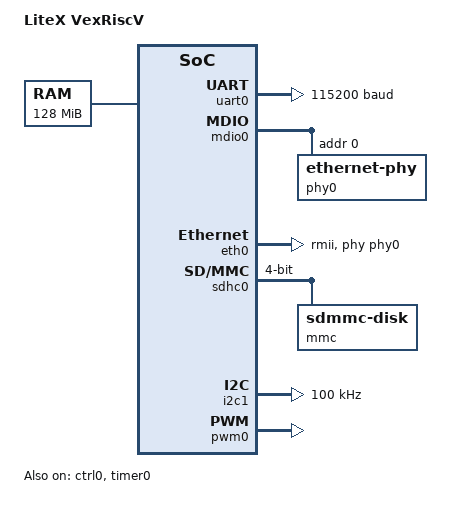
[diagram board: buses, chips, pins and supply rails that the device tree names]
/dts-v1/;

/* node '/' defined in zephyr/dts/riscv/riscv32-litex-vexriscv.dtsi:7 */
/ {
	#address-cells = < 0x1 >;      /* in zephyr/dts/riscv/riscv32-litex-vexriscv.dtsi:8 */
	#size-cells = < 0x1 >;         /* in zephyr/dts/riscv/riscv32-litex-vexriscv.dtsi:9 */
	model = "LiteX VexRiscV";      /* in zephyr/boards/enjoydigital/litex_vexriscv/litex_vexriscv.dts:13 */
	compatible = "litex,vexriscv"; /* in zephyr/boards/enjoydigital/litex_vexriscv/litex_vexriscv.dts:14 */

	/* node '/cpus' defined in zephyr/dts/riscv/riscv32-litex-vexriscv.dtsi:13 */
	cpus {
		#address-cells = < 0x1 >; /* in zephyr/dts/riscv/riscv32-litex-vexriscv.dtsi:14 */
		#size-cells = < 0x0 >;    /* in zephyr/dts/riscv/riscv32-litex-vexriscv.dtsi:15 */

		/* node '/cpus/cpu@0' defined in zephyr/dts/riscv/riscv32-litex-vexriscv.dtsi:17 */
		cpu0: cpu@0 {
			compatible = "litex,vexriscv-standard",
			             "spinalhdl,vexriscv",
			             "riscv";                   /* in zephyr/dts/riscv/riscv32-litex-vexriscv.dtsi:19 */
			device_type = "cpu";                    /* in zephyr/dts/riscv/riscv32-litex-vexriscv.dtsi:20 */
			reg = < 0x0 >;                          /* in zephyr/dts/riscv/riscv32-litex-vexriscv.dtsi:21 */
			riscv,isa-base = "rv32i";               /* in zephyr/dts/riscv/riscv32-litex-vexriscv.dtsi:22 */
			riscv,isa-extensions = "i",
			                       "m",
			                       "zicsr",
			                       "zifencei";      /* in zephyr/dts/riscv/riscv32-litex-vexriscv.dtsi:23 */
			status = "okay";                        /* in zephyr/dts/riscv/riscv32-litex-vexriscv.dtsi:24 */
			clock-frequency = < 0x2dc6c00 >;        /* in ../../build/rtos-system-fit/software/20261006T224900.204514Z/zephyr/generated/csr.overlay.dts:2 */
			i-cache-line-size = < 0x20 >;           /* in ../../build/rtos-system-fit/software/20261006T224900.204514Z/zephyr/generated/csr.overlay.dts:194 */
		};
	};

	/* node '/soc' defined in zephyr/dts/riscv/riscv32-litex-vexriscv.dtsi:28 */
	soc {
		#address-cells = < 0x1 >;      /* in zephyr/dts/riscv/riscv32-litex-vexriscv.dtsi:29 */
		#size-cells = < 0x1 >;         /* in zephyr/dts/riscv/riscv32-litex-vexriscv.dtsi:30 */
		compatible = "litex,vexriscv"; /* in zephyr/dts/riscv/riscv32-litex-vexriscv.dtsi:31 */
		ranges;                        /* in zephyr/dts/riscv/riscv32-litex-vexriscv.dtsi:32 */

		/* node '/soc/interrupt-controller@bc0' defined in zephyr/dts/riscv/riscv32-litex-vexriscv.dtsi:34 */
		intc0: interrupt-controller@bc0 {
			compatible = "litex,vexriscv-intc0"; /* in zephyr/dts/riscv/riscv32-litex-vexriscv.dtsi:35 */
			#address-cells = < 0x0 >;            /* in zephyr/dts/riscv/riscv32-litex-vexriscv.dtsi:36 */
			#interrupt-cells = < 0x2 >;          /* in zephyr/dts/riscv/riscv32-litex-vexriscv.dtsi:37 */
			interrupt-controller;                /* in zephyr/dts/riscv/riscv32-litex-vexriscv.dtsi:38 */
			reg = < 0xbc0 0x4 0xfc0 0x4 >;       /* in zephyr/dts/riscv/riscv32-litex-vexriscv.dtsi:39 */
			reg-names = "irq_mask",
			            "irq_pending";           /* in zephyr/dts/riscv/riscv32-litex-vexriscv.dtsi:40 */
			riscv,max-priority = < 0x7 >;        /* in zephyr/dts/riscv/riscv32-litex-vexriscv.dtsi:41 */
			phandle = < 0x1 >;                   /* in zephyr/boards/enjoydigital/litex_vexriscv/litex_vexriscv.dts:47 */
		};

		/* node '/soc/soc_controller@e0000000' defined in zephyr/boards/enjoydigital/litex_vexriscv/litex_vexriscv.dts:34 */
		ctrl0: soc_controller@e0000000 {
			compatible = "litex,soc-controller"; /* in zephyr/boards/enjoydigital/litex_vexriscv/litex_vexriscv.dts:35 */
			status = "okay";                     /* in zephyr/boards/enjoydigital/litex_vexriscv/litex_vexriscv.dts:42 */
			reg = < 0xf0000000 0x4 >,
			      < 0xf0000004 0x4 >,
			      < 0xf0000008 0x4 >;            /* in ../../build/rtos-system-fit/software/20261006T224900.204514Z/zephyr/generated/csr.overlay.dts:5 */
			reg-names = "reset",
			            "scratch",
			            "bus_errors";            /* in ../../build/rtos-system-fit/software/20261006T224900.204514Z/zephyr/generated/csr.overlay.dts:8 */
		};

		/* node '/soc/serial@e0001800' defined in zephyr/boards/enjoydigital/litex_vexriscv/litex_vexriscv.dts:45 */
		uart0: serial@e0001800 {
			compatible = "litex,uart";     /* in zephyr/boards/enjoydigital/litex_vexriscv/litex_vexriscv.dts:46 */
			interrupt-parent = < &intc0 >; /* in zephyr/boards/enjoydigital/litex_vexriscv/litex_vexriscv.dts:47 */
			status = "okay";               /* in zephyr/boards/enjoydigital/litex_vexriscv/litex_vexriscv.dts:65 */
			current-speed = < 0x1c200 >;   /* in zephyr/boards/enjoydigital/litex_vexriscv/litex_vexriscv.dts:66 */
			reg = < 0xf0004000 0x4 >,
			      < 0xf0004004 0x4 >,
			      < 0xf0004008 0x4 >,
			      < 0xf000400c 0x4 >,
			      < 0xf0004010 0x4 >,
			      < 0xf0004014 0x4 >,
			      < 0xf0004018 0x4 >,
			      < 0xf000401c 0x4 >;      /* in ../../build/rtos-system-fit/software/20261006T224900.204514Z/zephyr/generated/csr.overlay.dts:13 */
			reg-names = "rxtx",
			            "txfull",
			            "rxempty",
			            "ev_status",
			            "ev_pending",
			            "ev_enable",
			            "txempty",
			            "rxfull";          /* in ../../build/rtos-system-fit/software/20261006T224900.204514Z/zephyr/generated/csr.overlay.dts:21 */
			interrupts = < 0x0 0x1 >;      /* in ../../build/rtos-system-fit/software/20261006T224900.204514Z/zephyr/generated/csr.overlay.dts:29 */
		};

		/* node '/soc/timer@e0002800' defined in zephyr/boards/enjoydigital/litex_vexriscv/litex_vexriscv.dts:69 */
		timer0: timer@e0002800 {
			compatible = "litex,timer0";   /* in zephyr/boards/enjoydigital/litex_vexriscv/litex_vexriscv.dts:70 */
			interrupt-parent = < &intc0 >; /* in zephyr/boards/enjoydigital/litex_vexriscv/litex_vexriscv.dts:71 */
			status = "okay";               /* in zephyr/boards/enjoydigital/litex_vexriscv/litex_vexriscv.dts:93 */
			reg = < 0xf0003800 0x4 >,
			      < 0xf0003804 0x4 >,
			      < 0xf0003808 0x4 >,
			      < 0xf000380c 0x4 >,
			      < 0xf0003810 0x4 >,
			      < 0xf0003814 0x4 >,
			      < 0xf0003818 0x4 >,
			      < 0xf000381c 0x4 >,
			      < 0xf0003820 0x4 >,
			      < 0xf0003824 0x8 >;      /* in ../../build/rtos-system-fit/software/20261006T224900.204514Z/zephyr/generated/csr.overlay.dts:32 */
			reg-names = "load",
			            "reload",
			            "en",
			            "update_value",
			            "value",
			            "ev_status",
			            "ev_pending",
			            "ev_enable",
			            "uptime_latch",
			            "uptime_cycles";   /* in ../../build/rtos-system-fit/software/20261006T224900.204514Z/zephyr/generated/csr.overlay.dts:42 */
			interrupts = < 0x1 0x1 >;      /* in ../../build/rtos-system-fit/software/20261006T224900.204514Z/zephyr/generated/csr.overlay.dts:52 */
		};

		/* node '/soc/watchdog@e000d000' defined in zephyr/boards/enjoydigital/litex_vexriscv/litex_vexriscv.dts:96 */
		wdt0: watchdog@e000d000 {
			compatible = "litex,watchdog"; /* in zephyr/boards/enjoydigital/litex_vexriscv/litex_vexriscv.dts:97 */
			interrupt-parent = < &intc0 >; /* in zephyr/boards/enjoydigital/litex_vexriscv/litex_vexriscv.dts:98 */
			reg = < 0xe000d000 0x4 >,
			      < 0xe000d004 0x4 >,
			      < 0xe000d008 0x4 >,
			      < 0xe000d00c 0x4 >,
			      < 0xe000d010 0x4 >,
			      < 0xe000d014 0x4 >;      /* in zephyr/boards/enjoydigital/litex_vexriscv/litex_vexriscv.dts:99 */
			reg-names = "control",
			            "cycles",
			            "remaining",
			            "ev_status",
			            "ev_pending",
			            "ev_enable";       /* in zephyr/boards/enjoydigital/litex_vexriscv/litex_vexriscv.dts:105 */
			interrupts = < 0x8 0xf >;      /* in zephyr/boards/enjoydigital/litex_vexriscv/litex_vexriscv.dts:111 */
			status = "disabled";           /* in ../../build/rtos-system-fit/software/20261006T224900.204514Z/zephyr/generated/csr.overlay.dts:178 */
		};

		/* node '/soc/mdio@e0008000' defined in zephyr/boards/enjoydigital/litex_vexriscv/litex_vexriscv.dts:115 */
		mdio0: mdio@e0008000 {
			compatible = "litex,liteeth-mdio"; /* in zephyr/boards/enjoydigital/litex_vexriscv/litex_vexriscv.dts:116 */
			#address-cells = < 0x1 >;          /* in zephyr/boards/enjoydigital/litex_vexriscv/litex_vexriscv.dts:123 */
			#size-cells = < 0x0 >;             /* in zephyr/boards/enjoydigital/litex_vexriscv/litex_vexriscv.dts:124 */
			status = "okay";                   /* in zephyr/boards/enjoydigital/litex_vexriscv/litex_vexriscv.dts:125 */
			reg = < 0xf0001804 0x4 >,
			      < 0xf0001808 0x4 >;          /* in ../../build/rtos-system-fit/software/20261006T224900.204514Z/zephyr/generated/csr.overlay.dts:90 */
			reg-names = "mdio_w",
			            "mdio_r";              /* in ../../build/rtos-system-fit/software/20261006T224900.204514Z/zephyr/generated/csr.overlay.dts:92 */

			/* node '/soc/mdio@e0008000/ethernet-phy@1' defined in zephyr/boards/enjoydigital/litex_vexriscv/litex_vexriscv.dts:127 */
			phy0: ethernet-phy@1 {
				compatible = "ethernet-phy";            /* in zephyr/boards/enjoydigital/litex_vexriscv/litex_vexriscv.dts:128 */
				status = "okay";                        /* in zephyr/boards/enjoydigital/litex_vexriscv/litex_vexriscv.dts:130 */
				reg = < 0x0 >;                          /* in ../../build/rtos-system-fit/software/20261006T224900.204514Z/zephyr/generated/csr.overlay.dts:197 */
				default-speeds = "10BASE Half-Duplex",
				                 "10BASE Full-Duplex",
				                 "100BASE Half-Duplex",
				                 "100BASE Full-Duplex"; /* in ../../build/rtos-system-fit/software/20261006T224900.204514Z/zephyr/generated/csr.overlay.dts:197 */
				phandle = < 0x2 >;                      /* in zephyr/boards/enjoydigital/litex_vexriscv/litex_vexriscv.dts:169 */
			};
		};

		/* node '/soc/ethernet@e0009800' defined in zephyr/boards/enjoydigital/litex_vexriscv/litex_vexriscv.dts:134 */
		eth0: ethernet@e0009800 {
			compatible = "litex,liteeth";              /* in zephyr/boards/enjoydigital/litex_vexriscv/litex_vexriscv.dts:135 */
			interrupt-parent = < &intc0 >;             /* in zephyr/boards/enjoydigital/litex_vexriscv/litex_vexriscv.dts:136 */
			local-mac-address = [ 10 E2 D5 00 00 02 ]; /* in zephyr/boards/enjoydigital/litex_vexriscv/litex_vexriscv.dts:153 */
			phy-handle = < &phy0 >;                    /* in zephyr/boards/enjoydigital/litex_vexriscv/litex_vexriscv.dts:169 */
			status = "okay";                           /* in zephyr/boards/enjoydigital/litex_vexriscv/litex_vexriscv.dts:170 */
			reg = < 0xf0001000 0x4 >,
			      < 0xf0001004 0x4 >,
			      < 0xf0001008 0x4 >,
			      < 0xf000100c 0x4 >,
			      < 0xf0001010 0x4 >,
			      < 0xf0001014 0x4 >,
			      < 0xf0001018 0x4 >,
			      < 0xf000101c 0x4 >,
			      < 0xf0001020 0x4 >,
			      < 0xf0001024 0x4 >,
			      < 0xf0001028 0x4 >,
			      < 0xf000102c 0x4 >,
			      < 0xf0001030 0x4 >,
			      < 0xf0001034 0x4 >,
			      < 0x80000000 0x800 >,
			      < 0x80000800 0x800 >;                /* in ../../build/rtos-system-fit/software/20261006T224900.204514Z/zephyr/generated/csr.overlay.dts:55 */
			reg-names = "rx_slot",
			            "rx_length",
			            "rx_errors",
			            "rx_ev_status",
			            "rx_ev_pending",
			            "rx_ev_enable",
			            "tx_start",
			            "tx_ready",
			            "tx_level",
			            "tx_slot",
			            "tx_length",
			            "tx_ev_status",
			            "tx_ev_pending",
			            "tx_ev_enable",
			            "rx_buffers",
			            "tx_buffers";                  /* in ../../build/rtos-system-fit/software/20261006T224900.204514Z/zephyr/generated/csr.overlay.dts:71 */
			interrupts = < 0x2 0x1 >;                  /* in ../../build/rtos-system-fit/software/20261006T224900.204514Z/zephyr/generated/csr.overlay.dts:87 */
			phy-connection-type = "rmii";              /* in ../../build/rtos-system-fit/software/20261006T224900.204514Z/zephyr/generated/csr.overlay.dts:196 */
		};

		/* node '/soc/dna@e0003800' defined in zephyr/boards/enjoydigital/litex_vexriscv/litex_vexriscv.dts:173 */
		dna0: dna@e0003800 {
			compatible = "litex,dna0"; /* in zephyr/boards/enjoydigital/litex_vexriscv/litex_vexriscv.dts:174 */
			reg = < 0xe0003800 0x20 >; /* in zephyr/boards/enjoydigital/litex_vexriscv/litex_vexriscv.dts:181 */
			reg-names = "mem";         /* in zephyr/boards/enjoydigital/litex_vexriscv/litex_vexriscv.dts:182 */
			status = "disabled";       /* in ../../build/rtos-system-fit/software/20261006T224900.204514Z/zephyr/generated/csr.overlay.dts:187 */
		};

		/* node '/soc/spi@e0002000' defined in zephyr/boards/enjoydigital/litex_vexriscv/litex_vexriscv.dts:186 */
		spi0: spi@e0002000 {
			compatible = "litex,spi"; /* in zephyr/boards/enjoydigital/litex_vexriscv/litex_vexriscv.dts:187 */
			reg = < 0xe0002000 0x4 >,
			      < 0xe0002004 0x4 >,
			      < 0xe0002008 0x4 >,
			      < 0xe000200c 0x4 >,
			      < 0xe0002010 0x4 >,
			      < 0xe0002014 0x4 >; /* in zephyr/boards/enjoydigital/litex_vexriscv/litex_vexriscv.dts:188 */
			reg-names = "control",
			            "status",
			            "mosi",
			            "miso",
			            "cs",
			            "loopback";   /* in zephyr/boards/enjoydigital/litex_vexriscv/litex_vexriscv.dts:194 */
			#address-cells = < 0x1 >; /* in zephyr/boards/enjoydigital/litex_vexriscv/litex_vexriscv.dts:201 */
			#size-cells = < 0x0 >;    /* in zephyr/boards/enjoydigital/litex_vexriscv/litex_vexriscv.dts:202 */
			status = "disabled";      /* in ../../build/rtos-system-fit/software/20261006T224900.204514Z/zephyr/generated/csr.overlay.dts:96 */
		};

		/* node '/soc/spi@e000c000' defined in zephyr/boards/enjoydigital/litex_vexriscv/litex_vexriscv.dts:205 */
		spi1: spi@e000c000 {
			compatible = "litex,spi-litespi"; /* in zephyr/boards/enjoydigital/litex_vexriscv/litex_vexriscv.dts:206 */
			interrupt-parent = < &intc0 >;    /* in zephyr/boards/enjoydigital/litex_vexriscv/litex_vexriscv.dts:207 */
			reg = < 0xe000c000 0x4 >,
			      < 0xe000c004 0x4 >,
			      < 0xe000c008 0x4 >,
			      < 0xe000c00c 0x4 >,
			      < 0xe000c010 0x4 >,
			      < 0xe000c014 0x4 >,
			      < 0xe000c018 0x4 >,
			      < 0xe000c01c 0x4 >,
			      < 0xe000c020 0x4 >,
			      < 0x60000000 0x1000000 >;   /* in zephyr/boards/enjoydigital/litex_vexriscv/litex_vexriscv.dts:208 */
			reg-names = "phy_clk_divisor",
			            "mmap_dummy_bits",
			            "master_cs",
			            "master_phyconfig",
			            "master_rxtx",
			            "master_status",
			            "master_ev_status",
			            "master_ev_pending",
			            "master_ev_enable",
			            "flash_mmap";         /* in zephyr/boards/enjoydigital/litex_vexriscv/litex_vexriscv.dts:218 */
			interrupts = < 0x9 0x0 >;         /* in zephyr/boards/enjoydigital/litex_vexriscv/litex_vexriscv.dts:228 */
			#address-cells = < 0x1 >;         /* in zephyr/boards/enjoydigital/litex_vexriscv/litex_vexriscv.dts:229 */
			#size-cells = < 0x0 >;            /* in zephyr/boards/enjoydigital/litex_vexriscv/litex_vexriscv.dts:230 */
			status = "disabled";              /* in ../../build/rtos-system-fit/software/20261006T224900.204514Z/zephyr/generated/csr.overlay.dts:99 */

			/* node '/soc/spi@e000c000/flash@0' defined in zephyr/boards/enjoydigital/litex_vexriscv/litex_vexriscv.dts:232 */
			spiflash0: flash@0 {
				compatible = "jedec,spi-nor";     /* in zephyr/boards/enjoydigital/litex_vexriscv/litex_vexriscv.dts:233 */
				reg = < 0x0 >;                    /* in zephyr/boards/enjoydigital/litex_vexriscv/litex_vexriscv.dts:234 */
				spi-max-frequency = < 0x989680 >; /* in zephyr/boards/enjoydigital/litex_vexriscv/litex_vexriscv.dts:235 */
			};
		};

		/* node '/soc/sdhc@e000e800' defined in zephyr/boards/enjoydigital/litex_vexriscv/litex_vexriscv.dts:239 */
		sdhc0: sdhc@e000e800 {
			compatible = "litex,mmc";           /* in zephyr/boards/enjoydigital/litex_vexriscv/litex_vexriscv.dts:240 */
			interrupt-parent = < &intc0 >;      /* in zephyr/boards/enjoydigital/litex_vexriscv/litex_vexriscv.dts:241 */
			status = "okay";                    /* in zephyr/boards/enjoydigital/litex_vexriscv/litex_vexriscv.dts:303 */
			reg = < 0xf0002800 0x4 >,
			      < 0xf0002804 0x4 >,
			      < 0xf0002808 0x4 >,
			      < 0xf000280c 0x4 >,
			      < 0xf0002810 0x4 >,
			      < 0xf0002814 0x4 >,
			      < 0xf0002818 0x4 >,
			      < 0xf000281c 0x4 >,
			      < 0xf0002820 0x4 >,
			      < 0xf0002824 0x4 >,
			      < 0xf0002828 0x10 >,
			      < 0xf0002838 0x4 >,
			      < 0xf000283c 0x4 >,
			      < 0xf0002840 0x4 >,
			      < 0xf0002844 0x4 >,
			      < 0xf0002848 0x8 >,
			      < 0xf0002850 0x4 >,
			      < 0xf0002854 0x4 >,
			      < 0xf0002858 0x4 >,
			      < 0xf000285c 0x4 >,
			      < 0xf0002860 0x4 >,
			      < 0xf0002864 0x4 >,
			      < 0xf0002868 0x8 >,
			      < 0xf0002870 0x4 >,
			      < 0xf0002874 0x4 >,
			      < 0xf0002878 0x4 >,
			      < 0xf000287c 0x4 >,
			      < 0xf0002880 0x4 >,
			      < 0xf0002884 0x4 >,
			      < 0xf0002888 0x4 >,
			      < 0xf000288c 0x4 >,
			      < 0xf0002890 0x4 >;           /* in ../../build/rtos-system-fit/software/20261006T224900.204514Z/zephyr/generated/csr.overlay.dts:102 */
			reg-names = "phy_card_detect",
			            "phy_clocker_divider",
			            "phy_init_initialize",
			            "phy_cmdr_timeout",
			            "phy_dataw_status",
			            "phy_datar_timeout",
			            "phy_settings",
			            "core_cmd_argument",
			            "core_cmd_command",
			            "core_cmd_send",
			            "core_cmd_response",
			            "core_cmd_event",
			            "core_data_event",
			            "core_block_length",
			            "core_block_count",
			            "block2mem_dma_base",
			            "block2mem_dma_length",
			            "block2mem_dma_enable",
			            "block2mem_dma_done",
			            "block2mem_dma_loop",
			            "block2mem_dma_offset",
			            "block2mem_dma_error",
			            "mem2block_dma_base",
			            "mem2block_dma_length",
			            "mem2block_dma_enable",
			            "mem2block_dma_done",
			            "mem2block_dma_loop",
			            "mem2block_dma_offset",
			            "mem2block_dma_error",
			            "ev_status",
			            "ev_pending",
			            "ev_enable";            /* in ../../build/rtos-system-fit/software/20261006T224900.204514Z/zephyr/generated/csr.overlay.dts:134 */
			interrupts = < 0x3 0x1 >;           /* in ../../build/rtos-system-fit/software/20261006T224900.204514Z/zephyr/generated/csr.overlay.dts:166 */
			bus-width = < 0x4 >;                /* in ../../build/rtos-system-fit/software/20261006T224900.204514Z/zephyr/generated/csr.overlay.dts:195 */

			/* node '/soc/sdhc@e000e800/mmc' defined in zephyr/boards/enjoydigital/litex_vexriscv/litex_vexriscv.dts:305 */
			mmc {
				compatible = "zephyr,sdmmc-disk"; /* in zephyr/boards/enjoydigital/litex_vexriscv/litex_vexriscv.dts:306 */
				status = "okay";                  /* in zephyr/boards/enjoydigital/litex_vexriscv/litex_vexriscv.dts:307 */
				disk-name = "SD";                 /* in zephyr/boards/enjoydigital/litex_vexriscv/litex_vexriscv.dts:308 */
			};
		};

		/* node '/soc/prbs@e0006800' defined in zephyr/boards/enjoydigital/litex_vexriscv/litex_vexriscv.dts:312 */
		prbs0: prbs@e0006800 {
			compatible = "litex,prbs"; /* in zephyr/boards/enjoydigital/litex_vexriscv/litex_vexriscv.dts:313 */
			reg = < 0xe0006800 0x4 >;  /* in zephyr/boards/enjoydigital/litex_vexriscv/litex_vexriscv.dts:314 */
			reg-names = "status";      /* in zephyr/boards/enjoydigital/litex_vexriscv/litex_vexriscv.dts:315 */
			status = "disabled";       /* in ../../build/rtos-system-fit/software/20261006T224900.204514Z/zephyr/generated/csr.overlay.dts:190 */
		};

		/* node '/soc/i2c@e0005000' defined in zephyr/boards/enjoydigital/litex_vexriscv/litex_vexriscv.dts:319 */
		i2c0: i2c@e0005000 {
			compatible = "litex,i2c";      /* in zephyr/boards/enjoydigital/litex_vexriscv/litex_vexriscv.dts:320 */
			reg = < 0xe0005000 0x4 >,
			      < 0xe0005004 0x4 >;      /* in zephyr/boards/enjoydigital/litex_vexriscv/litex_vexriscv.dts:321 */
			reg-names = "write",
			            "read";            /* in zephyr/boards/enjoydigital/litex_vexriscv/litex_vexriscv.dts:323 */
			clock-frequency = < 0x186a0 >; /* in zephyr/boards/enjoydigital/litex_vexriscv/litex_vexriscv.dts:325 */
			#address-cells = < 0x1 >;      /* in zephyr/boards/enjoydigital/litex_vexriscv/litex_vexriscv.dts:326 */
			#size-cells = < 0x0 >;         /* in zephyr/boards/enjoydigital/litex_vexriscv/litex_vexriscv.dts:327 */
			status = "disabled";           /* in ../../build/rtos-system-fit/software/20261006T224900.204514Z/zephyr/generated/csr.overlay.dts:169 */
		};

		/* node '/soc/i2c@e000d800' defined in zephyr/boards/enjoydigital/litex_vexriscv/litex_vexriscv.dts:331 */
		i2c1: i2c@e000d800 {
			compatible = "litex,litei2c";    /* in zephyr/boards/enjoydigital/litex_vexriscv/litex_vexriscv.dts:332 */
			interrupt-parent = < &intc0 >;   /* in zephyr/boards/enjoydigital/litex_vexriscv/litex_vexriscv.dts:333 */
			reg = < 0xe000d800 0x4 >,
			      < 0xe000d804 0x4 >,
			      < 0xe000d808 0x4 >,
			      < 0xe000d80c 0x4 >,
			      < 0xe000d810 0x4 >,
			      < 0xe000d814 0x4 >,
			      < 0xe000d818 0x4 >,
			      < 0xe000d81c 0x4 >,
			      < 0xe000d820 0x4 >;        /* in zephyr/boards/enjoydigital/litex_vexriscv/litex_vexriscv.dts:334 */
			reg-names = "phy_speed_mode",
			            "master_active",
			            "master_settings",
			            "master_addr",
			            "master_rxtx",
			            "master_status",
			            "master_ev_status",
			            "master_ev_pending",
			            "master_ev_enable";  /* in zephyr/boards/enjoydigital/litex_vexriscv/litex_vexriscv.dts:343 */
			interrupts = < 0xa 0x0 >;        /* in zephyr/boards/enjoydigital/litex_vexriscv/litex_vexriscv.dts:352 */
			clock-frequency = < 0x186a0 >;   /* in zephyr/boards/enjoydigital/litex_vexriscv/litex_vexriscv.dts:353 */
			#address-cells = < 0x1 >;        /* in zephyr/boards/enjoydigital/litex_vexriscv/litex_vexriscv.dts:354 */
			#size-cells = < 0x0 >;           /* in zephyr/boards/enjoydigital/litex_vexriscv/litex_vexriscv.dts:355 */
			status = "okay";                 /* in zephyr/boards/enjoydigital/litex_vexriscv/litex_vexriscv.dts:356 */
		};

		/* node '/soc/pwm@e0007000' defined in zephyr/boards/enjoydigital/litex_vexriscv/litex_vexriscv.dts:359 */
		pwm0: pwm@e0007000 {
			compatible = "litex,pwm";  /* in zephyr/boards/enjoydigital/litex_vexriscv/litex_vexriscv.dts:360 */
			reg = < 0xe0007000 0x4 >,
			      < 0xe0007004 0x10 >,
			      < 0xe0007014 0x10 >; /* in zephyr/boards/enjoydigital/litex_vexriscv/litex_vexriscv.dts:361 */
			reg-names = "enable",
			            "width",
			            "period";      /* in zephyr/boards/enjoydigital/litex_vexriscv/litex_vexriscv.dts:364 */
			status = "okay";           /* in zephyr/boards/enjoydigital/litex_vexriscv/litex_vexriscv.dts:367 */
			#pwm-cells = < 0x2 >;      /* in zephyr/boards/enjoydigital/litex_vexriscv/litex_vexriscv.dts:368 */
		};

		/* node '/soc/gpio@e0005800' defined in zephyr/boards/enjoydigital/litex_vexriscv/litex_vexriscv.dts:371 */
		gpio_out: gpio@e0005800 {
			compatible = "litex,gpio"; /* in zephyr/boards/enjoydigital/litex_vexriscv/litex_vexriscv.dts:372 */
			reg = < 0xe0005800 0x4 >;  /* in zephyr/boards/enjoydigital/litex_vexriscv/litex_vexriscv.dts:373 */
			reg-names = "out";         /* in zephyr/boards/enjoydigital/litex_vexriscv/litex_vexriscv.dts:374 */
			ngpios = < 0x4 >;          /* in zephyr/boards/enjoydigital/litex_vexriscv/litex_vexriscv.dts:375 */
			gpio-controller;           /* in zephyr/boards/enjoydigital/litex_vexriscv/litex_vexriscv.dts:377 */
			#gpio-cells = < 0x2 >;     /* in zephyr/boards/enjoydigital/litex_vexriscv/litex_vexriscv.dts:378 */
			status = "disabled";       /* in ../../build/rtos-system-fit/software/20261006T224900.204514Z/zephyr/generated/csr.overlay.dts:198 */
		};

		/* node '/soc/gpio@e0006000' defined in zephyr/boards/enjoydigital/litex_vexriscv/litex_vexriscv.dts:381 */
		gpio_in: gpio@e0006000 {
			compatible = "litex,gpio";     /* in zephyr/boards/enjoydigital/litex_vexriscv/litex_vexriscv.dts:382 */
			reg = < 0xe0006000 0x4 >,
			      < 0xe0006004 0x4 >,
			      < 0xe0006008 0x4 >,
			      < 0xe0006010 0x4 >,
			      < 0xe0006014 0x4 >;      /* in zephyr/boards/enjoydigital/litex_vexriscv/litex_vexriscv.dts:383 */
			interrupt-parent = < &intc0 >; /* in zephyr/boards/enjoydigital/litex_vexriscv/litex_vexriscv.dts:388 */
			interrupts = < 0x4 0x2 >;      /* in zephyr/boards/enjoydigital/litex_vexriscv/litex_vexriscv.dts:389 */
			reg-names = "in",
			            "mode",
			            "edge",
			            "ev_pending",
			            "ev_enable";       /* in zephyr/boards/enjoydigital/litex_vexriscv/litex_vexriscv.dts:390 */
			ngpios = < 0x4 >;              /* in zephyr/boards/enjoydigital/litex_vexriscv/litex_vexriscv.dts:395 */
			gpio-controller;               /* in zephyr/boards/enjoydigital/litex_vexriscv/litex_vexriscv.dts:397 */
			#gpio-cells = < 0x2 >;         /* in zephyr/boards/enjoydigital/litex_vexriscv/litex_vexriscv.dts:398 */
			status = "disabled";           /* in ../../build/rtos-system-fit/software/20261006T224900.204514Z/zephyr/generated/csr.overlay.dts:199 */
		};

		/* node '/soc/i2s_rx@e000a800' defined in zephyr/boards/enjoydigital/litex_vexriscv/litex_vexriscv.dts:401 */
		i2s_rx: i2s_rx@e000a800 {
			compatible = "litex,i2s";      /* in zephyr/boards/enjoydigital/litex_vexriscv/litex_vexriscv.dts:402 */
			reg = < 0xe000a800 0x4 >,
			      < 0xe000a804 0x4 >,
			      < 0xe000a808 0x4 >,
			      < 0xe000a80c 0x4 >,
			      < 0xe000a810 0x4 >,
			      < 0xe000a814 0x4 >,
			      < 0xb1000000 0x40000 >;  /* in zephyr/boards/enjoydigital/litex_vexriscv/litex_vexriscv.dts:403 */
			interrupt-parent = < &intc0 >; /* in zephyr/boards/enjoydigital/litex_vexriscv/litex_vexriscv.dts:410 */
			interrupts = < 0x6 0x2 >;      /* in zephyr/boards/enjoydigital/litex_vexriscv/litex_vexriscv.dts:411 */
			#address-cells = < 0x1 >;      /* in zephyr/boards/enjoydigital/litex_vexriscv/litex_vexriscv.dts:412 */
			#size-cells = < 0x0 >;         /* in zephyr/boards/enjoydigital/litex_vexriscv/litex_vexriscv.dts:413 */
			reg-names = "ev_status",
			            "ev_pending",
			            "ev_enable",
			            "rx_ctl",
			            "rx_stat",
			            "rx_conf",
			            "fifo";            /* in zephyr/boards/enjoydigital/litex_vexriscv/litex_vexriscv.dts:414 */
			fifo-depth = < 0x100 >;        /* in zephyr/boards/enjoydigital/litex_vexriscv/litex_vexriscv.dts:421 */
			status = "disabled";           /* in ../../build/rtos-system-fit/software/20261006T224900.204514Z/zephyr/generated/csr.overlay.dts:172 */
		};

		/* node '/soc/i2s_tx@e000b000' defined in zephyr/boards/enjoydigital/litex_vexriscv/litex_vexriscv.dts:425 */
		i2s_tx: i2s_tx@e000b000 {
			compatible = "litex,i2s";      /* in zephyr/boards/enjoydigital/litex_vexriscv/litex_vexriscv.dts:426 */
			reg = < 0xe000b000 0x4 >,
			      < 0xe000b004 0x4 >,
			      < 0xe000b008 0x4 >,
			      < 0xe000b00c 0x4 >,
			      < 0xe000b010 0x4 >,
			      < 0xe000b014 0x4 >,
			      < 0xb2000000 0x40000 >;  /* in zephyr/boards/enjoydigital/litex_vexriscv/litex_vexriscv.dts:427 */
			interrupt-parent = < &intc0 >; /* in zephyr/boards/enjoydigital/litex_vexriscv/litex_vexriscv.dts:434 */
			interrupts = < 0x7 0x2 >;      /* in zephyr/boards/enjoydigital/litex_vexriscv/litex_vexriscv.dts:435 */
			#address-cells = < 0x1 >;      /* in zephyr/boards/enjoydigital/litex_vexriscv/litex_vexriscv.dts:436 */
			#size-cells = < 0x0 >;         /* in zephyr/boards/enjoydigital/litex_vexriscv/litex_vexriscv.dts:437 */
			reg-names = "ev_status",
			            "ev_pending",
			            "ev_enable",
			            "tx_ctl",
			            "tx_stat",
			            "tx_conf",
			            "fifo";            /* in zephyr/boards/enjoydigital/litex_vexriscv/litex_vexriscv.dts:438 */
			fifo-depth = < 0x100 >;        /* in zephyr/boards/enjoydigital/litex_vexriscv/litex_vexriscv.dts:445 */
			status = "disabled";           /* in ../../build/rtos-system-fit/software/20261006T224900.204514Z/zephyr/generated/csr.overlay.dts:175 */
		};

		/* node '/soc/clock-outputs' defined in zephyr/boards/enjoydigital/litex_vexriscv/litex_vexriscv.dts:449 */
		clock-outputs {
			#address-cells = < 0x1 >; /* in zephyr/boards/enjoydigital/litex_vexriscv/litex_vexriscv.dts:450 */
			#size-cells = < 0x0 >;    /* in zephyr/boards/enjoydigital/litex_vexriscv/litex_vexriscv.dts:451 */

			/* node '/soc/clock-outputs/clock-controller@0' defined in zephyr/boards/enjoydigital/litex_vexriscv/litex_vexriscv.dts:453 */
			clk0: clock-controller@0 {
				#clock-cells = < 0x1 >;               /* in zephyr/boards/enjoydigital/litex_vexriscv/litex_vexriscv.dts:454 */
				reg = < 0x0 >;                        /* in zephyr/boards/enjoydigital/litex_vexriscv/litex_vexriscv.dts:455 */
				compatible = "litex,clkout";          /* in zephyr/boards/enjoydigital/litex_vexriscv/litex_vexriscv.dts:456 */
				clock-output-names = "CLK_0";         /* in zephyr/boards/enjoydigital/litex_vexriscv/litex_vexriscv.dts:457 */
				litex,clock-frequency = < 0xac4400 >; /* in zephyr/boards/enjoydigital/litex_vexriscv/litex_vexriscv.dts:458 */
				litex,clock-phase = < 0x0 >;          /* in zephyr/boards/enjoydigital/litex_vexriscv/litex_vexriscv.dts:459 */
				litex,clock-duty-num = < 0x1 >;       /* in zephyr/boards/enjoydigital/litex_vexriscv/litex_vexriscv.dts:460 */
				litex,clock-duty-den = < 0x2 >;       /* in zephyr/boards/enjoydigital/litex_vexriscv/litex_vexriscv.dts:461 */
				litex,clock-margin = < 0x1 >;         /* in zephyr/boards/enjoydigital/litex_vexriscv/litex_vexriscv.dts:462 */
				litex,clock-margin-exp = < 0x2 >;     /* in zephyr/boards/enjoydigital/litex_vexriscv/litex_vexriscv.dts:463 */
				status = "okay";                      /* in zephyr/boards/enjoydigital/litex_vexriscv/litex_vexriscv.dts:464 */
				phandle = < 0x3 >;                    /* in zephyr/boards/enjoydigital/litex_vexriscv/litex_vexriscv.dts:501 */
			};

			/* node '/soc/clock-outputs/clock-controller@1' defined in zephyr/boards/enjoydigital/litex_vexriscv/litex_vexriscv.dts:467 */
			clk1: clock-controller@1 {
				#clock-cells = < 0x1 >;                /* in zephyr/boards/enjoydigital/litex_vexriscv/litex_vexriscv.dts:468 */
				reg = < 0x1 >;                         /* in zephyr/boards/enjoydigital/litex_vexriscv/litex_vexriscv.dts:469 */
				compatible = "litex,clkout";           /* in zephyr/boards/enjoydigital/litex_vexriscv/litex_vexriscv.dts:470 */
				clock-output-names = "CLK_1";          /* in zephyr/boards/enjoydigital/litex_vexriscv/litex_vexriscv.dts:471 */
				litex,clock-frequency = < 0x1588800 >; /* in zephyr/boards/enjoydigital/litex_vexriscv/litex_vexriscv.dts:472 */
				litex,clock-phase = < 0x0 >;           /* in zephyr/boards/enjoydigital/litex_vexriscv/litex_vexriscv.dts:473 */
				litex,clock-duty-num = < 0x1 >;        /* in zephyr/boards/enjoydigital/litex_vexriscv/litex_vexriscv.dts:474 */
				litex,clock-duty-den = < 0x2 >;        /* in zephyr/boards/enjoydigital/litex_vexriscv/litex_vexriscv.dts:475 */
				litex,clock-margin = < 0x1 >;          /* in zephyr/boards/enjoydigital/litex_vexriscv/litex_vexriscv.dts:476 */
				litex,clock-margin-exp = < 0x2 >;      /* in zephyr/boards/enjoydigital/litex_vexriscv/litex_vexriscv.dts:477 */
				status = "okay";                       /* in zephyr/boards/enjoydigital/litex_vexriscv/litex_vexriscv.dts:478 */
				phandle = < 0x4 >;                     /* in zephyr/boards/enjoydigital/litex_vexriscv/litex_vexriscv.dts:501 */
			};
		};

		/* node '/soc/clock@e0004800' defined in zephyr/boards/enjoydigital/litex_vexriscv/litex_vexriscv.dts:482 */
		clock0: clock@e0004800 {
			compatible = "litex,clk";            /* in zephyr/boards/enjoydigital/litex_vexriscv/litex_vexriscv.dts:483 */
			reg = < 0xe0004800 0x4 >,
			      < 0xe0004804 0x4 >,
			      < 0xe0004808 0x4 >,
			      < 0xe000480c 0x4 >,
			      < 0xe0004810 0x4 >,
			      < 0xe0004814 0x4 >,
			      < 0xe0004818 0x4 >,
			      < 0xe000481c 0x4 >;            /* in zephyr/boards/enjoydigital/litex_vexriscv/litex_vexriscv.dts:484 */
			reg-names = "drp_reset",
			            "drp_locked",
			            "drp_read",
			            "drp_write",
			            "drp_drdy",
			            "drp_adr",
			            "drp_dat_w",
			            "drp_dat_r";             /* in zephyr/boards/enjoydigital/litex_vexriscv/litex_vexriscv.dts:492 */
			#clock-cells = < 0x1 >;              /* in zephyr/boards/enjoydigital/litex_vexriscv/litex_vexriscv.dts:500 */
			clocks = < &clk0 0x0 >,
			         < &clk1 0x1 >;              /* in zephyr/boards/enjoydigital/litex_vexriscv/litex_vexriscv.dts:501 */
			clock-output-names = "CLK_0",
			                     "CLK_1";        /* in zephyr/boards/enjoydigital/litex_vexriscv/litex_vexriscv.dts:502 */
			litex,lock-timeout = < 0xa >;        /* in zephyr/boards/enjoydigital/litex_vexriscv/litex_vexriscv.dts:503 */
			litex,drdy-timeout = < 0xa >;        /* in zephyr/boards/enjoydigital/litex_vexriscv/litex_vexriscv.dts:504 */
			litex,divclk-divide-min = < 0x1 >;   /* in zephyr/boards/enjoydigital/litex_vexriscv/litex_vexriscv.dts:505 */
			litex,divclk-divide-max = < 0x6b >;  /* in zephyr/boards/enjoydigital/litex_vexriscv/litex_vexriscv.dts:506 */
			litex,clkfbout-mult-min = < 0x2 >;   /* in zephyr/boards/enjoydigital/litex_vexriscv/litex_vexriscv.dts:507 */
			litex,clkfbout-mult-max = < 0x41 >;  /* in zephyr/boards/enjoydigital/litex_vexriscv/litex_vexriscv.dts:508 */
			litex,vco-freq-min = < 0x23c34600 >; /* in zephyr/boards/enjoydigital/litex_vexriscv/litex_vexriscv.dts:509 */
			litex,vco-freq-max = < 0x47868c00 >; /* in zephyr/boards/enjoydigital/litex_vexriscv/litex_vexriscv.dts:510 */
			litex,clkout-divide-min = < 0x1 >;   /* in zephyr/boards/enjoydigital/litex_vexriscv/litex_vexriscv.dts:511 */
			litex,clkout-divide-max = < 0x7e >;  /* in zephyr/boards/enjoydigital/litex_vexriscv/litex_vexriscv.dts:512 */
			litex,vco-margin = < 0x0 >;          /* in zephyr/boards/enjoydigital/litex_vexriscv/litex_vexriscv.dts:513 */
			status = "disabled";                 /* in ../../build/rtos-system-fit/software/20261006T224900.204514Z/zephyr/generated/csr.overlay.dts:181 */
		};
	};

	/* node '/chosen' defined in zephyr/boards/enjoydigital/litex_vexriscv/litex_vexriscv.dts:16 */
	chosen {
		zephyr,console = &uart0;    /* in zephyr/boards/enjoydigital/litex_vexriscv/litex_vexriscv.dts:17 */
		zephyr,shell-uart = &uart0; /* in zephyr/boards/enjoydigital/litex_vexriscv/litex_vexriscv.dts:18 */
		zephyr,sram = &ram0;        /* in zephyr/boards/enjoydigital/litex_vexriscv/litex_vexriscv.dts:19 */
	};

	/* node '/aliases' defined in zephyr/boards/enjoydigital/litex_vexriscv/litex_vexriscv.dts:23 */
	aliases {
		sdhc0 = &sdhc0;    /* in zephyr/boards/enjoydigital/litex_vexriscv/litex_vexriscv.dts:24 */
		watchdog0 = &wdt0; /* in zephyr/boards/enjoydigital/litex_vexriscv/litex_vexriscv.dts:25 */
	};

	/* node '/memory@40000000' defined in zephyr/boards/enjoydigital/litex_vexriscv/litex_vexriscv.dts:28 */
	ram0: memory@40000000 {
		device_type = "memory";         /* in zephyr/boards/enjoydigital/litex_vexriscv/litex_vexriscv.dts:29 */
		reg = < 0x40000000 0x8000000 >; /* in ../../build/rtos-system-fit/software/20261006T224900.204514Z/zephyr/generated/csr.overlay.dts:184 */
	};
};
